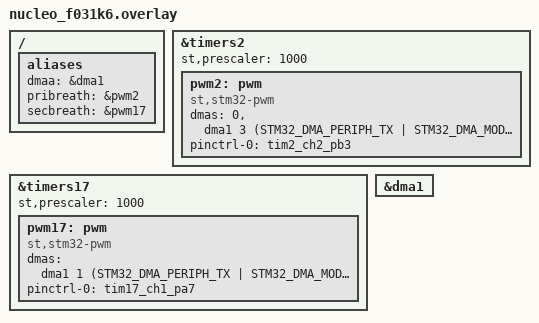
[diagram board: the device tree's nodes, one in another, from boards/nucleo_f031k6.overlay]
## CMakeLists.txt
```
# SPDX-FileCopyrightText: Copyright The Zephyr Project Contributors
# SPDX-License-Identifier: Apache-2.0

cmake_minimum_required(VERSION 3.20.0)

find_package(Zephyr REQUIRED HINTS $ENV{ZEPHYR_BASE})
project(circular_dma)

target_sources(app PRIVATE src/main.c)
```

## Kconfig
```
#
# SPDX-FileCopyrightText: Copyright The Zephyr Project Contributors
# SPDX-License-Identifier: Apache-2.0
#

mainmenu "Breathing Led sample application"

config PRIMARY_BREATH_CHANNEL
	int "Timer channel for the primary led on this board"
	default 0

config SECONDARY_BREATH_CHANNEL
	int "Timer channel for the secondary breath output on this board"
	default 0

source "Kconfig.zephyr"
```

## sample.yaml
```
sample:
  name: PWM with DMA sample
tests:
  sample.boards.stm32.uart.circular_dma:
    integration_platforms:
      - nucleo_f412zg
    tags:
      - pwm
      - dma
    filter: dt_chosen_enabled("zephyr,shell-uart") and CONFIG_SOC_FAMILY_STM32
    harness: keyboard
```

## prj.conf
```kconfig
CONFIG_PWM=y
CONFIG_PWM_DMA=y
CONFIG_DMA=y
```

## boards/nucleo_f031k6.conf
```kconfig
CONFIG_PRIMARY_BREATH_CHANNEL=2
CONFIG_SECONDARY_BREATH_CHANNEL=1
```

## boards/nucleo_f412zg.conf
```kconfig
CONFIG_PRIMARY_BREATH_CHANNEL=3
CONFIG_SECONDARY_BREATH_CHANNEL=2
```

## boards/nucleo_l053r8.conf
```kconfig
CONFIG_PRIMARY_BREATH_CHANNEL=1
CONFIG_SECONDARY_BREATH_CHANNEL=3
```

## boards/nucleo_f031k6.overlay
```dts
/*
 * SPDX-FileCopyrightText: Copyright The Zephyr Project Contributors
 * SPDX-License-Identifier: Apache-2.0
 */
/ {
	aliases {
		dmaa = &dma1;
		pribreath = &pwm2;
		secbreath = &pwm17;
	};
};


&timers2 {
	st,prescaler = <1000>;
	status = "okay";

	pwm2: pwm {
		compatible = "st,stm32-pwm";
		status = "okay";
		/* I could not find a better way to assign the dmas to the timer channel
		than listing them in order here. The result is that unused channels before
		used channels have to be listed as <0>.
		Unused channels after used ones can be ommitted. */
		dmas = <0>,
			   <&dma1 3 (STM32_DMA_PERIPH_TX | STM32_DMA_MODE_CYCLIC | STM32_DMA_PRIORITY_HIGH | STM32_DMA_MEM_32BITS | STM32_DMA_PERIPH_32BITS)>;

		dma-names = "tch1", "tch2"; // the number of entries here must match the number of dmas entries above
		pinctrl-0 = <&tim2_ch2_pb3>;
		pinctrl-names = "default";
	};
};

&timers17 {
	st,prescaler = <1000>;
	status = "okay";

	pwm17: pwm {
		compatible = "st,stm32-pwm";
		/* I could not find a better way to assign the dmas to the timer channel
		than listing them in order here. The result is that unused channels before
		used channels have to be listed as <0>.
		Unused channels after used ones can be ommitted. */
		dmas = <&dma1 1 (STM32_DMA_PERIPH_TX | STM32_DMA_MODE_CYCLIC | STM32_DMA_PRIORITY_HIGH | STM32_DMA_MEM_32BITS | STM32_DMA_PERIPH_32BITS)>;
		dma-names = "tch1"; // the number of entries here must match the number of dmas entries above
		pinctrl-0 = <&tim17_ch1_pa7>;
		pinctrl-names = "default";
		status = "okay";
	};
};

&dma1 {
	status = "okay";
};
```

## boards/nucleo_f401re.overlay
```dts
/*
 * SPDX-FileCopyrightText: Copyright The Zephyr Project Contributors
 * SPDX-License-Identifier: Apache-2.0
 */

/ {
 	aliases {
		dmaa = &dma1;
		pribreath = &pwm2;
		secbreath = &pwm2;
	};
};

&timers2 {
	st,prescaler = <1000>;
	status = "okay";

	pwm2: pwm {
		/* I could not find a better way to assign the dmas to the timer channel
		than listing them in order here. The result is that unused channels before
		used channels have to be listed as <0>.
		Unused channels after used ones can be ommitted. */
		dmas = <&dma1 5 3 (STM32_DMA_PERIPH_TX | STM32_DMA_MODE_CYCLIC | STM32_DMA_PRIORITY_HIGH | STM32_DMA_MEM_32BITS | STM32_DMA_PERIPH_32BITS) STM32_DMA_FIFO_FULL>,
		       <0>,
		       <&dma1 1 3 (STM32_DMA_PERIPH_TX | STM32_DMA_MODE_CYCLIC | STM32_DMA_PRIORITY_HIGH | STM32_DMA_MEM_32BITS | STM32_DMA_PERIPH_32BITS) STM32_DMA_FIFO_FULL>;
		dma-names = "tch1", "tch2", "tch3"; // the number of entries here must match the number of dmas entries above
		pinctrl-0 = <&tim2_ch1_pa5>, <&tim2_ch3_pb10>;
		pinctrl-names = "default";
		status = "okay";
	};
};

&dma1 {
	status = "okay";
};
```

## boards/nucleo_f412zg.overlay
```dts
/*
 * SPDX-FileCopyrightText: Copyright The Zephyr Project Contributors
 * SPDX-License-Identifier: Apache-2.0
 */

/ {
	aliases {
		dmaa = &dma1;
		pribreath = &pwm3;
		secbreath = &pwm4;
	};
};

&timers3 {
	st,prescaler = <1000>;
	status = "okay";
	
	pwm3: pwm {
		/* I could not find a better way to assign the dmas to the timer channel
		than listing them in order here. The result is that unused channels before
		used channels have to be listed as <0>.
		Unused channels after used ones can be ommitted. */
		dmas = <0>,
		       <0>,
		       <&dma1 7 5 (STM32_DMA_PERIPH_TX | STM32_DMA_MODE_CYCLIC | STM32_DMA_PRIORITY_HIGH | STM32_DMA_MEM_32BITS | STM32_DMA_PERIPH_32BITS) STM32_DMA_FIFO_FULL>,
		       <0>;
		dma-names = "tch1", "tch2", "tch3", "tch4"; // the number of entries here must match the number of dmas entries above
		pinctrl-0 = <&tim3_ch3_pb0>;
		pinctrl-names = "default";
		status = "okay";
	};
};

&timers4 {
	st,prescaler = <1000>;
	status = "okay";
	
	pwm4: pwm {
		/* I could not find a better way to assign the dmas to the timer channel
		than listing them in order here. The result is that unused channels before
		used channels have to be listed as <0>.
		Unused channels after used ones can be ommitted. */
		dmas = <0>,
		       <&dma1 3 2 (STM32_DMA_PERIPH_TX | STM32_DMA_MODE_CYCLIC | STM32_DMA_PRIORITY_HIGH | STM32_DMA_MEM_32BITS | STM32_DMA_PERIPH_32BITS) STM32_DMA_FIFO_FULL>,
		       <0>,
		       <0>;
		dma-names = "tch1", "tch2", "tch3", "tch4"; // the number of entries here must match the number of dmas entries above
		pinctrl-0 = <&tim4_ch2_pb7>;
		pinctrl-names = "default";
		status = "okay";
	};
};

&dma1 {
	status = "okay";
};
```

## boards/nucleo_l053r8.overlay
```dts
/*
 * SPDX-FileCopyrightText: Copyright The Zephyr Project Contributors
 * SPDX-License-Identifier: Apache-2.0
 */
/ {
	aliases {
		dmaa = &dma1;
		pribreath = &pwm2;
		secbreath = &pwm2;
};
};


&timers2 {
	st,prescaler = <1000>;
	status = "okay";

	pwm2: pwm {
		/* I could not find a better way to assign the dmas to the timer channel
		than listing them in order here. The result is that unused channels before
		used channels have to be listed as <0>.
		Unused channels after used ones can be ommitted. */
		dmas = <&dma1 5 8 (STM32_DMA_PERIPH_TX | STM32_DMA_MODE_CYCLIC | STM32_DMA_PRIORITY_HIGH | STM32_DMA_MEM_32BITS | STM32_DMA_PERIPH_32BITS)>,
		       <0>,
		       <&dma1 1 8 (STM32_DMA_PERIPH_TX | STM32_DMA_MODE_CYCLIC | STM32_DMA_PRIORITY_HIGH | STM32_DMA_MEM_32BITS | STM32_DMA_PERIPH_32BITS)>;
		dma-names = "tch1", "tch2", "tch3"; // the number of entries here must match the number of dmas entries above
		pinctrl-0 = <&tim2_ch1_pa5>, <&tim2_ch3_pb10>;
		pinctrl-names = "default";
		status = "okay";
	};
};

&dma1 {
	status = "okay";
};
```

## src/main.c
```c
/*
 * SPDX-License-Identifier: Apache-2.0
 */

#include <zephyr/kernel.h>
#include <zephyr/device.h>
#include <zephyr/devicetree.h>
#include <zephyr/drivers/pwm.h>
#include <zephyr/drivers/dma.h>
#include <zephyr/sys/printk.h>

static const struct device *const dma_dev = DEVICE_DT_GET(DT_ALIAS(dmaa));
static const struct device *const pwm_led_dev = DEVICE_DT_GET(DT_ALIAS(pribreath));
static const struct device *const pwm_sec_out_dev = DEVICE_DT_GET(DT_ALIAS(secbreath));


uint32_t ledPeriod = 20000000; // 20 ms 
uint32_t pwmTableLed[] = {
	1000000, 1600000, 2200000, 2800000, 3400000, 4000000, 4600000, 5200000,
	5800000, 6400000, 7000000, 7600000, 8200000, 8800000, 9400000, 10000000,
	10600000, 11200000, 11800000, 12400000, 13000000, 13600000, 14200000, 14800000,
	15400000, 16000000, 16600000, 17200000, 17800000, 18400000, 19000000, 18400000,
	17800000, 17200000, 16600000, 16000000, 15400000, 14800000, 14200000, 13600000,
	13000000, 12400000, 11800000, 11200000, 10600000, 10000000, 9400000, 8800000,
	8200000, 7600000, 7000000, 6400000, 5800000, 5200000, 4600000, 4000000,
	3400000, 2800000, 2200000, 1600000
};

uint32_t pwmTableOut[] = {
	1000000, 2200000, 3400000, 4600000, 5800000, 7000000, 8200000, 9400000,
	10600000, 11800000, 13000000, 14200000, 15400000, 16600000, 17800000, 19000000,
	17800000, 16600000, 15400000, 14200000, 13000000, 11800000, 10600000, 9400000,
	8200000, 7000000, 5800000, 4600000, 3400000, 2200000, 1600000
};

int main(void)
{
	if (!device_is_ready(pwm_led_dev)) {
		printk("PWM device is not ready\n");
		return 0;
	}

	if (!device_is_ready(pwm_sec_out_dev)) {
		printk("PWM device is not ready\n");
		return 0;
	}

	if (!device_is_ready(dma_dev)) {
		printk("DMA device is not ready\n");
		return 0;
	}

	pwm_set_dma(pwm_led_dev, CONFIG_PRIMARY_BREATH_CHANNEL, ledPeriod, pwmTableLed, sizeof(pwmTableLed) / sizeof(uint32_t), PWM_POLARITY_NORMAL);
	pwm_set_dma(pwm_sec_out_dev, CONFIG_SECONDARY_BREATH_CHANNEL, ledPeriod, pwmTableOut, sizeof(pwmTableOut) / sizeof(uint32_t), PWM_POLARITY_NORMAL);

	while (1) {
		k_msleep(500);
	}

}
```
